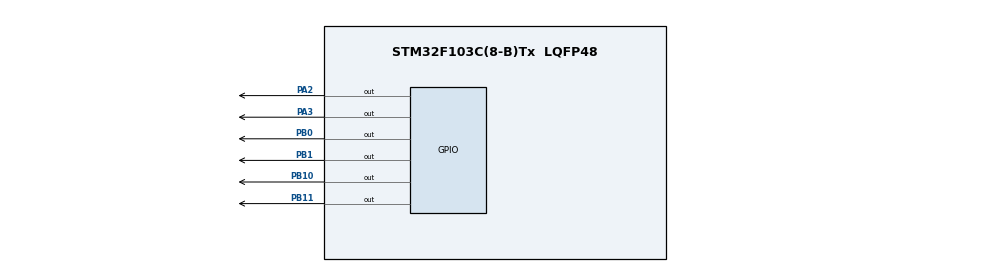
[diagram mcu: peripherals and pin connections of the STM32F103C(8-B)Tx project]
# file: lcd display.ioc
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Mcu.Family=STM32F1
Mcu.Name=STM32F103C(8-B)Tx
Mcu.Package=LQFP48
NVIC.PriorityGroup=NVIC_PRIORITYGROUP_4
PA13.Mode=Serial_Wire
PA13.Signal=SYS_JTMS-SWDIO
PA14.Mode=Serial_Wire
PA14.Signal=SYS_JTCK-SWCLK
PA2.GPIO_Speed=GPIO_SPEED_FREQ_HIGH
PA2.Signal=GPIO_Output
PA3.GPIO_Speed=GPIO_SPEED_FREQ_HIGH
PA3.Signal=GPIO_Output
PB0.GPIO_Speed=GPIO_SPEED_FREQ_HIGH
PB0.Signal=GPIO_Output
PB1.GPIO_Speed=GPIO_SPEED_FREQ_HIGH
PB1.Signal=GPIO_Output
PB10.GPIO_Speed=GPIO_SPEED_FREQ_HIGH
PB10.Signal=GPIO_Output
PB11.GPIO_Speed=GPIO_SPEED_FREQ_HIGH
PB11.Signal=GPIO_Output
ProjectManager.HeapSize=0x200
ProjectManager.StackSize=0x400
ProjectManager.TargetToolchain=STM32CubeIDE
RCC.APB1Freq_Value=8000000
RCC.APB2Freq_Value=8000000
board=custom

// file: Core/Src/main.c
/* USER CODE BEGIN Header */
/**
  ******************************************************************************
  * @file           : main.c
  * @brief          : Main program body
  ******************************************************************************
  * @attention
  *
  * <h2><center>&copy; Copyright (c) 2021 STMicroelectronics.
  * All rights reserved.</center></h2>
  *
  * This software component is licensed by ST under BSD 3-Clause license,
  * the "License"; You may not use this file except in compliance with the
  * License. You may obtain a copy of the License at:
  *                        opensource.org/licenses/BSD-3-Clause
  *
  ******************************************************************************
  */
/* USER CODE END Header */
#include "main.h"

/* USER CODE BEGIN Includes */
#include "lcd.h"
/* USER CODE END Includes */

void SystemClock_Config(void);
static void MX_GPIO_Init(void);

int main(void)
{

  /* MCU Configuration--------------------------------------------------------*/

  /* Reset of all peripherals, Initializes the Flash interface and the Systick. */
  HAL_Init();

  /* Configure the system clock */
  SystemClock_Config();

  /* Initialize all configured peripherals */
  MX_GPIO_Init();
  /* USER CODE BEGIN 2 */
  Lcd_PortType ports[] = { GPIOB, GPIOB, GPIOB, GPIOB };
    Lcd_PinType pins[] = {GPIO_PIN_0, GPIO_PIN_1, GPIO_PIN_10, GPIO_PIN_11};
    Lcd_HandleTypeDef lcd;
    lcd = Lcd_create(ports, pins, GPIOA, GPIO_PIN_2, GPIOA, GPIO_PIN_3, LCD_4_BIT_MODE);
    Lcd_cursor(&lcd, 0,1);
    Lcd_string(&lcd, "TPET");
    for ( int x = 1; x <= 1000; x++)
    {
  	  Lcd_cursor(&lcd, 1,7);
  	  Lcd_int(&lcd, x);
  	  HAL_Delay (1000);
    }
  /* USER CODE END 2 */

  /* Infinite loop */
  while (1)
  {

  }
}

void SystemClock_Config(void)
{
  RCC_OscInitTypeDef RCC_OscInitStruct = {0};
  RCC_ClkInitTypeDef RCC_ClkInitStruct = {0};

  /** Initializes the RCC Oscillators according to the specified parameters
  * in the RCC_OscInitTypeDef structure.
  */
  RCC_OscInitStruct.OscillatorType = RCC_OSCILLATORTYPE_HSI;
  RCC_OscInitStruct.HSIState = RCC_HSI_ON;
  RCC_OscInitStruct.HSICalibrationValue = RCC_HSICALIBRATION_DEFAULT;
  RCC_OscInitStruct.PLL.PLLState = RCC_PLL_NONE;
  if (HAL_RCC_OscConfig(&RCC_OscInitStruct) != HAL_OK)
  {
    Error_Handler();
  }
  /** Initializes the CPU, AHB and APB buses clocks
  */
  RCC_ClkInitStruct.ClockType = RCC_CLOCKTYPE_HCLK|RCC_CLOCKTYPE_SYSCLK
                              |RCC_CLOCKTYPE_PCLK1|RCC_CLOCKTYPE_PCLK2;
  RCC_ClkInitStruct.SYSCLKSource = RCC_SYSCLKSOURCE_HSI;
  RCC_ClkInitStruct.AHBCLKDivider = RCC_SYSCLK_DIV1;
  RCC_ClkInitStruct.APB1CLKDivider = RCC_HCLK_DIV1;
  RCC_ClkInitStruct.APB2CLKDivider = RCC_HCLK_DIV1;

  if (HAL_RCC_ClockConfig(&RCC_ClkInitStruct, FLASH_LATENCY_0) != HAL_OK)
  {
    Error_Handler();
  }
}

static void MX_GPIO_Init(void)
{
  GPIO_InitTypeDef GPIO_InitStruct = {0};

  /* GPIO Ports Clock Enable */
  __HAL_RCC_GPIOA_CLK_ENABLE();
  __HAL_RCC_GPIOB_CLK_ENABLE();

  /*Configure GPIO pin Output Level */
  HAL_GPIO_WritePin(GPIOA, GPIO_PIN_2|GPIO_PIN_3, GPIO_PIN_RESET);

  /*Configure GPIO pin Output Level */
  HAL_GPIO_WritePin(GPIOB, GPIO_PIN_0|GPIO_PIN_1|GPIO_PIN_10|GPIO_PIN_11, GPIO_PIN_RESET);

  /*Configure GPIO pins : PA2 PA3 */
  GPIO_InitStruct.Pin = GPIO_PIN_2|GPIO_PIN_3;
  GPIO_InitStruct.Mode = GPIO_MODE_OUTPUT_PP;
  GPIO_InitStruct.Pull = GPIO_NOPULL;
  GPIO_InitStruct.Speed = GPIO_SPEED_FREQ_HIGH;
  HAL_GPIO_Init(GPIOA, &GPIO_InitStruct);

  /*Configure GPIO pins : PB0 PB1 PB10 PB11 */
  GPIO_InitStruct.Pin = GPIO_PIN_0|GPIO_PIN_1|GPIO_PIN_10|GPIO_PIN_11;
  GPIO_InitStruct.Mode = GPIO_MODE_OUTPUT_PP;
  GPIO_InitStruct.Pull = GPIO_NOPULL;
  GPIO_InitStruct.Speed = GPIO_SPEED_FREQ_HIGH;
  HAL_GPIO_Init(GPIOB, &GPIO_InitStruct);

}

void Error_Handler(void)
{
  __disable_irq();
  while (1)
  {
  }
}

/************************ (C) COPYRIGHT STMicroelectronics *****END OF FILE****/
